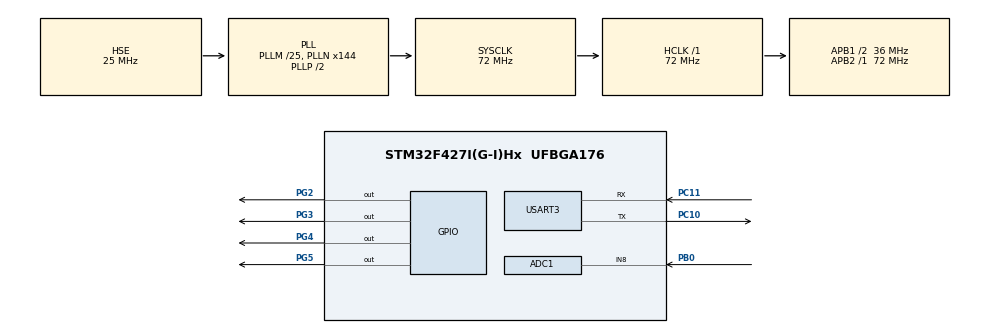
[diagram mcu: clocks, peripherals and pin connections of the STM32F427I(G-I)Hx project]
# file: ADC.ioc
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ADC1.Channel-3\#ChannelRegularConversion=ADC_CHANNEL_8
ADC1.Channel-4\#ChannelInjectedConversion=ADC_CHANNEL_8
ADC1.ContinuousConvMode=ENABLE
ADC1.InjNumberOfConversion=1
ADC1.InjectedOffset-4\#ChannelInjectedConversion=0
ADC1.InjectedRank-4\#ChannelInjectedConversion=1
ADC1.NbrOfConversionFlag=1
ADC1.Rank-3\#ChannelRegularConversion=1
ADC1.SamplingTime-3\#ChannelRegularConversion=ADC_SAMPLETIME_3CYCLES
ADC1.SamplingTime-4\#ChannelInjectedConversion=ADC_SAMPLETIME_3CYCLES
ADC1.master=1
Mcu.Family=STM32F4
Mcu.Name=STM32F427I(G-I)Hx
Mcu.Package=UFBGA176
NVIC.ADC_IRQn=true\:0\:0\:false\:false\:true\:true\:true
NVIC.PriorityGroup=NVIC_PRIORITYGROUP_4
NVIC.USART3_IRQn=true\:0\:0\:false\:false\:true\:true\:true
PB0.Signal=ADCx_IN8
PC10.Mode=Asynchronous
PC10.Signal=USART3_TX
PC11.Mode=Asynchronous
PC11.Signal=USART3_RX
PG2.Signal=GPIO_Output
PG3.Signal=GPIO_Output
PG4.Signal=GPIO_Output
PG5.Signal=GPIO_Output
PH0/OSC_IN.Mode=HSE-External-Oscillator
PH0/OSC_IN.Signal=RCC_OSC_IN
PH1/OSC_OUT.Mode=HSE-External-Oscillator
PH1/OSC_OUT.Signal=RCC_OSC_OUT
ProjectManager.HeapSize=0x200
ProjectManager.StackSize=0x400
ProjectManager.TargetToolchain=MDK-ARM V5
RCC.48MHZClocksFreq_Value=36000000
RCC.AHBFreq_Value=72000000
RCC.APB1CLKDivider=RCC_HCLK_DIV2
RCC.APB1Freq_Value=36000000
RCC.APB1TimFreq_Value=72000000
RCC.APB2Freq_Value=72000000
RCC.APB2TimFreq_Value=72000000
RCC.CortexFreq_Value=72000000
RCC.HCLKFreq_Value=72000000
RCC.HSE_VALUE=25000000
RCC.HSI_VALUE=16000000
RCC.LSE_VALUE=32768
RCC.PLLM=25
RCC.PLLN=144
RCC.PLLSourceVirtual=RCC_PLLSOURCE_HSE
RCC.SYSCLKFreq_VALUE=72000000
RCC.SYSCLKSource=RCC_SYSCLKSOURCE_PLLCLK
RCC.VCOOutputFreq_Value=144000000
SH.ADCx_IN8.0=ADC1_IN8,IN8
USART3.VirtualMode=VM_ASYNC
board=custom

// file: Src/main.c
/* USER CODE BEGIN Header */
/**
  ******************************************************************************
  * @file           : main.c
  * @brief          : Main program body
  ******************************************************************************
  * @attention
  *
  * <h2><center>&copy; Copyright (c) 2022 STMicroelectronics.
  * All rights reserved.</center></h2>
  *
  * This software component is licensed by ST under BSD 3-Clause license,
  * the "License"; You may not use this file except in compliance with the
  * License. You may obtain a copy of the License at:
  *                        opensource.org/licenses/BSD-3-Clause
  *
  ******************************************************************************
  */
/* USER CODE END Header */

#include "main.h"
#include "adc.h"
#include "usart.h"
#include "gpio.h"

/* USER CODE BEGIN PV */
uint16_t ADC_value;     //adc读值
uint16_t result;
/* USER CODE END PV */

void SystemClock_Config(void);
/* USER CODE BEGIN PFP */
int ADC_get()
{
	HAL_ADC_Start(&hadc1);	//启动ADC转换
	HAL_ADC_PollForConversion(&hadc1, 50);	//等待转换完成，50ms为最大等待时间
	if(HAL_IS_BIT_SET(HAL_ADC_GetState(&hadc1), HAL_ADC_STATE_REG_EOC))
	{
		ADC_value = HAL_ADC_GetValue(&hadc1);		//获取AD值
	}
	return ADC_value;
}
/* USER CODE END PFP */

int main(void)
{

  /* MCU Configuration--------------------------------------------------------*/

  /* Reset of all peripherals, Initializes the Flash interface and the Systick. */
  HAL_Init();

  /* Configure the system clock */
  SystemClock_Config();

  /* Initialize all configured peripherals */
  MX_GPIO_Init();
  MX_ADC1_Init();
  MX_USART3_UART_Init();

  /* Infinite loop */
  while (1)
  {

    /* USER CODE BEGIN 3 */

		result = ADC_get();
		/*HAL_ADC_Start(&hadc1);	//启动ADC转换
		HAL_ADC_PollForConversion(&hadc1, 50);	//等待转换完成，50ms为最大等待时间
		if(HAL_IS_BIT_SET(HAL_ADC_GetState(&hadc1), HAL_ADC_STATE_REG_EOC))
		{
			ADC_value = HAL_ADC_GetValue(&hadc1);		//获取AD值
			//HAL_GPIO_TogglePin(GPIOG, GPIO_PIN_2);
			//HAL_Delay(ADC_value);
			if(ADC_value > 3000 && ADC_value <= 3250)
			{
				HAL_GPIO_WritePin(GPIOG, GPIO_PIN_2,1);
				HAL_Delay(1000);
			}
			else if (ADC_value > 3250 && ADC_value <= 3500)
			{
				HAL_GPIO_WritePin(GPIOG, GPIO_PIN_2,1);
				HAL_GPIO_WritePin(GPIOG, GPIO_PIN_3,1);
				//HAL_Delay(1000);
			}
			else if (ADC_value > 3500 && ADC_value <= 3750)
			{
				HAL_GPIO_WritePin(GPIOG, GPIO_PIN_2,1);
				HAL_GPIO_WritePin(GPIOG, GPIO_PIN_3,1);
				HAL_GPIO_WritePin(GPIOG, GPIO_PIN_4,1);
				//HAL_Delay(1000);
			}
			else if (ADC_value > 3750 && ADC_value <= 4000)
			{
				HAL_GPIO_WritePin(GPIOG, GPIO_PIN_2,1);
				HAL_GPIO_WritePin(GPIOG, GPIO_PIN_3,1);
				HAL_GPIO_WritePin(GPIOG, GPIO_PIN_4,1);
				HAL_GPIO_WritePin(GPIOG, GPIO_PIN_5,1);
				//HAL_Delay(1000);
			}
			printf("ADC1 Reading : %d \r\n",ADC_value);
			printf("PB0 True Voltage value : %.4f \r\n",ADC_value*3.3f/4096);
			printf("测试\r\n");
		}
		//HAL_Delay(1000);*/

  }
  /* USER CODE END 3 */
}

void SystemClock_Config(void)
{
  RCC_OscInitTypeDef RCC_OscInitStruct = {0};
  RCC_ClkInitTypeDef RCC_ClkInitStruct = {0};

  /** Configure the main internal regulator output voltage
  */
  __HAL_RCC_PWR_CLK_ENABLE();
  __HAL_PWR_VOLTAGESCALING_CONFIG(PWR_REGULATOR_VOLTAGE_SCALE3);
  /** Initializes the CPU, AHB and APB busses clocks
  */
  RCC_OscInitStruct.OscillatorType = RCC_OSCILLATORTYPE_HSE;
  RCC_OscInitStruct.HSEState = RCC_HSE_ON;
  RCC_OscInitStruct.PLL.PLLState = RCC_PLL_ON;
  RCC_OscInitStruct.PLL.PLLSource = RCC_PLLSOURCE_HSE;
  RCC_OscInitStruct.PLL.PLLM = 25;
  RCC_OscInitStruct.PLL.PLLN = 144;
  RCC_OscInitStruct.PLL.PLLP = RCC_PLLP_DIV2;
  RCC_OscInitStruct.PLL.PLLQ = 4;
  if (HAL_RCC_OscConfig(&RCC_OscInitStruct) != HAL_OK)
  {
    Error_Handler();
  }
  /** Initializes the CPU, AHB and APB busses clocks
  */
  RCC_ClkInitStruct.ClockType = RCC_CLOCKTYPE_HCLK|RCC_CLOCKTYPE_SYSCLK
                              |RCC_CLOCKTYPE_PCLK1|RCC_CLOCKTYPE_PCLK2;
  RCC_ClkInitStruct.SYSCLKSource = RCC_SYSCLKSOURCE_PLLCLK;
  RCC_ClkInitStruct.AHBCLKDivider = RCC_SYSCLK_DIV1;
  RCC_ClkInitStruct.APB1CLKDivider = RCC_HCLK_DIV2;
  RCC_ClkInitStruct.APB2CLKDivider = RCC_HCLK_DIV1;

  if (HAL_RCC_ClockConfig(&RCC_ClkInitStruct, FLASH_LATENCY_2) != HAL_OK)
  {
    Error_Handler();
  }
}

void Error_Handler(void)
{
}

/************************ (C) COPYRIGHT STMicroelectronics *****END OF FILE****/
